# PIC32MK0512MCJ064 device description
Architecture: MIPS; Family: PIC32MK; Series: PIC32MK
Registers are 32-bit, read-write, no defined reset value unless marked. A register's access mark holds for its fields unless they carry their own. Offsets are from the block's base; [hi:lo] are bit positions; {n}, {i} and the like mark numbered series; 'fields as' and 'values as' point back to an identical list.

## DSCTRL
Instances: DSCTRL 0x1f8c0200 in periph_pb6_std
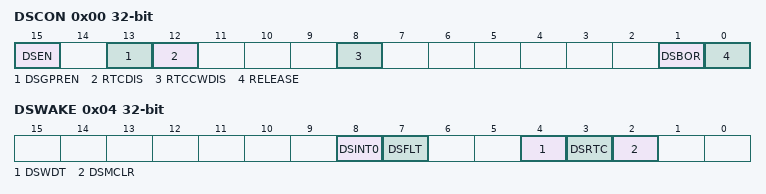
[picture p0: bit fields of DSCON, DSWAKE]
0x00 DSCON — Deep Sleep Control Register
  [15] DSEN — Deep Sleep Enable bit
    1=Deep Sleep mode is entered on a WAIT command; 0=Sleep mode is entered on a WAIT command
  [13] DSGPREN — General Purpose Registers Enable bit
    1=General purpose register retention is enabled in Deep Sleep mode; 0=No general purpose register retention in Deep Sleep mode
  [12] RTCDIS — RTCC Module Disable bit
    1=RTCC module is not enabled; 0=RTCC module is enabled
  [8] RTCCWDIS — RTCC Wake-up Disable bit
    1=Wake-up from RTCC is disabled; 0=Wake-up from RTCC is enabled
  [1] DSBOR — Deep Sleep BOR Event Status bit
    1=DSBOREN was enabled and VDD dropped below the DSBOR threshold during Deep Sleep; 0=DSBOREN was disabled, or VDD did not drop below the DSBOR threshold during Deep Sleep
  [0] RELEASE — I/O Pin State Release bit
    1=Upon waking from Deep Sleep, the I/O pins maintain their previous states; 0=Release I/O pins and allow their respective TRIS and LAT bits to control their states
0x04 DSWAKE — Deep Sleep Wake-up Source Register
  [8] DSINT0 — Interrupt-on-Change bit
    1=Interrupt-on-change was asserted during Deep Sleep; 0=Interrupt-on-change was not asserted during Deep Sleep
  [7] DSFLT — Deep Sleep Fault Detected bit
    1=A Fault occurred during Deep Sleep and some Deep Sleep configuration settings may have been corrupted; 0=No Fault was detected during Deep Sleep
  [4] DSWDT — Deep Sleep Watchdog Timer Time-out bit
    1=The Deep Sleep Watchdog Timer timed out during Deep Sleep; 0=The Deep Sleep Watchdog Timer did not time-out during Deep Sleep
  [3] DSRTC — Real-Time Clock and Calendar Alarm bit
    1=The Real-Time Clock and Calendar triggered an alarm during Deep Sleep; 0=The Real-Time Clock and Calendar did not trigger an alarm during Deep Sleep
  [2] DSMCLR — MCLR Event bit
    1=The MCLR pin was active and was asserted during Deep Sleep; 0=The MCLR pin was not active, or was active, but not asserted during Deep Sleep
0x08 DSGPR0
  [31:0] DSGPR
{0xC+4i} DSGPR{i} (i=1..32)
  [31:0] DSGPR

## HLVD
Instances: HLVD 0x1f801800 in periph_pb1_std
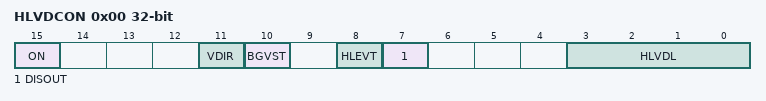
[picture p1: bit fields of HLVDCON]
0x00 HLVDCON — High/Low-Voltage Detect Control Register
  [15] ON — HLVD Module Enable bit
    1=HLVD module is enabled; 0=HLVD module is disabled
  [11] VDIR — Voltage Change Direction Select bit
    1=Event occurs when voltage equals or exceeds the trip point (HLVDL); 0=Event occurs when voltage equals or falls below the trip point (HLVDL)
  [10] BGVST — Band Gap Reference Voltages Stable Status bit
    1=Indicates internal band gap voltage references is stable; 0=Indicates internal band gap voltage reference is not stable
  [8] HLEVT — High/Low-Voltage Detection Event Status bit
    1=Indicates HLVD Event is active; 0=Indicates HLVD Event is not active
  [7] DISOUT — Disable HLVD Output bit
    1=Enable output of HLVD Comparator. Once set, can only be cleared by setting the ON bit to 0.; 0=Disable output of HLVD Comparator (default Reset value)
  [3:0] HLVDL — High/Low-Voltage Detection Limit Select bits
    15=1.2V (Selects external LVDIN pin); 10=2.4V; 9=2.5V; 8=2.69V; 7=2.791V; 6=3.0V; 5=3.288V; 4=3.529V

## ICAP
Instances: ICAP 0x1f822000 in periph_pb2_std
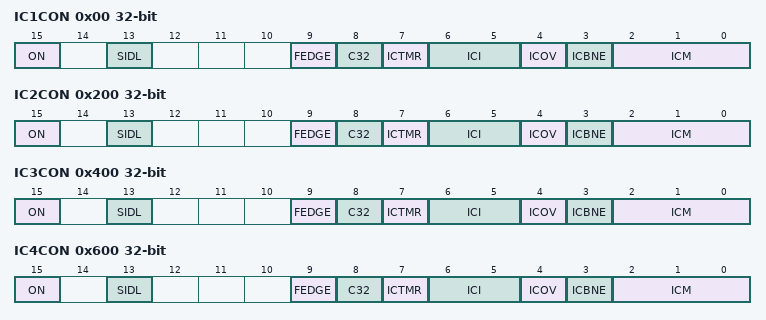
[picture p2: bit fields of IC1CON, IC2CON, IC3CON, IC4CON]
0x00 IC1CON — Input Capture x Control Register
  [15] ON — Input Capture Module Enable bit
    1=Module is enabled; 0=Disable and reset module
  [13] SIDL — Stop in Idle Control bit
    1=Halt in CPU Idle mode; 0=Continue to operate in CPU Idle mode
  [9] FEDGE — First Capture Edge Select bit
    1=Capture rising edge first; 0=Capture falling edge first
  [8] C32 — 32-bit Capture Select bit
    1=32-bit timer resource capture; 0=16-bit timer resource capture
  [7] ICTMR — Timer Select bit
    0=Timery is the counter source for capture; 1=Timerx is the counter source for capture
  [6:5] ICI — Interrupt Control bits
    3=Interrupt on every fourth capture event; 2=Interrupt on every third capture event; 1=Interrupt on every second capture event; 0=Interrupt on every capture event
  [4] ICOV — Input Capture Overflow Status Flag bit
    1=Input capture overflow is occurred; 0=No input capture overflow is occurred
  [3] ICBNE — Input Capture Buffer Not Empty Status bit
    1=Input capture buffer is not empty; at least one more capture value can be read; 0=Input capture buffer is empty
  [2:0] ICM — Input Capture Mode Select bits
    7=Interrupt-Only mode (only supported while in Sleep mode or Idle mode); 6=Simple Capture Event mode every edge; 5=Prescaled Capture Event mode every sixteenth rising edge; 4=Prescaled Capture Event mode every fourth rising edge; 3=Simple Capture Event mode every rising edge; 2=Simple Capture Event mode every falling edge; 1=Edge Detect mode every edge (rising and falling); 0=Input Capture module is disabled
0x10 IC1BUF ro
0x200 IC2CON — Input Capture x Control Register
  fields as IC1CON
0x210 IC2BUF ro
0x400 IC3CON — Input Capture x Control Register
  fields as IC1CON
0x410 IC3BUF ro
0x600 IC4CON — Input Capture x Control Register
  fields as IC1CON
0x610 IC4BUF ro
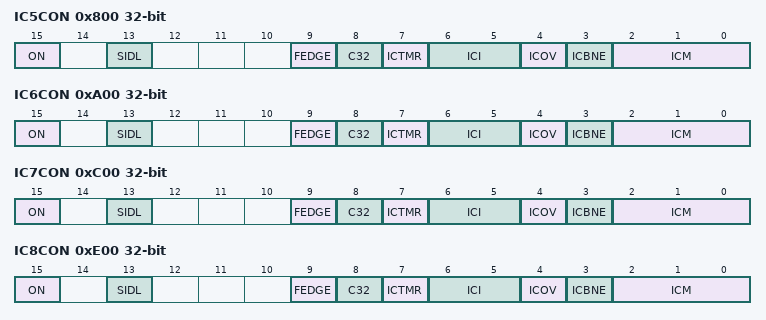
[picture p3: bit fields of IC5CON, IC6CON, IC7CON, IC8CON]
0x800 IC5CON — Input Capture x Control Register
  fields as IC1CON
0x810 IC5BUF ro
0xA00 IC6CON — Input Capture x Control Register
  fields as IC1CON
0xA10 IC6BUF ro
0xC00 IC7CON — Input Capture x Control Register
  fields as IC1CON
0xC10 IC7BUF ro
0xE00 IC8CON — Input Capture x Control Register
  fields as IC1CON
0xE10 IC8BUF ro
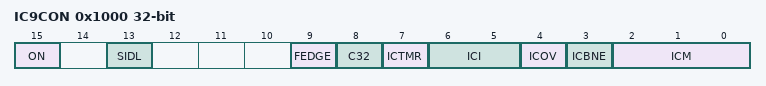
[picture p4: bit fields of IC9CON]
0x1000 IC9CON — Input Capture x Control Register
  fields as IC1CON
0x1010 IC9BUF ro

## Notices in the file
Copyright (c) 2019 Microchip Technology Inc.
SPDX-License-Identifier: Apache-2.0
Licensed under the Apache License, Version 2.0 (the "License");
you may not use this file except in compliance with the License.
You may obtain a copy of the License at
http://www.apache.org/licenses/LICENSE-2.0
Unless required by applicable law or agreed to in writing, software
distributed under the License is distributed on an "AS IS" BASIS,
WITHOUT WARRANTIES OR CONDITIONS OF ANY KIND, either express or implied.
See the License for the specific language governing permissions and
limitations under the License.
